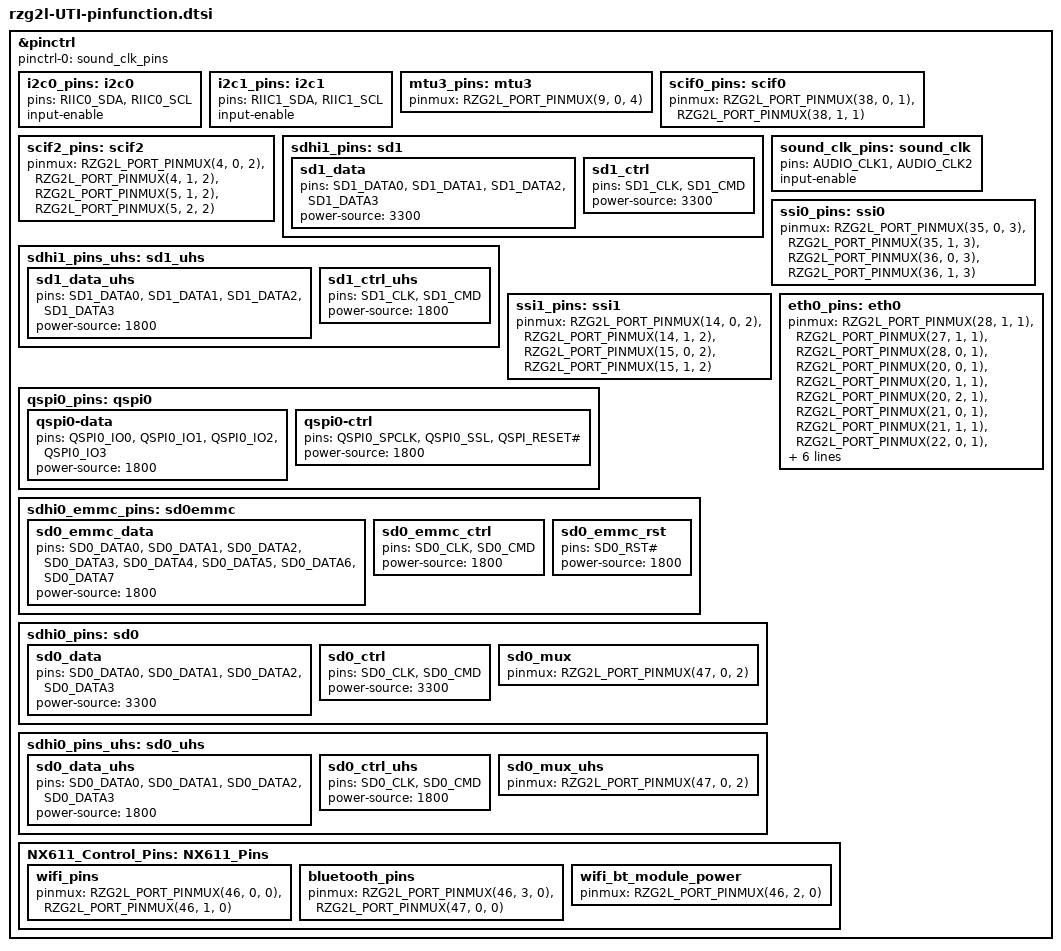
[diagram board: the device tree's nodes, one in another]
// SPDX-License-Identifier: (GPL-2.0-only OR BSD-2-Clause)
/*
 * Device Tree Source for the RZ/{G2L,V2L} SMARC pincontrol parts
 *
 * Copyright (C) 2021 Renesas Electronics Corp.
 */

#include <dt-bindings/gpio/gpio.h>
#include <dt-bindings/pinctrl/rzg2l-pinctrl.h>

&pinctrl {
	pinctrl-0 = <&sound_clk_pins>;
	pinctrl-names = "default";

	i2c0_pins: i2c0 {
		pins = "RIIC0_SDA", "RIIC0_SCL";
		input-enable;
	};

	i2c1_pins: i2c1 {
		pins = "RIIC1_SDA", "RIIC1_SCL";
		input-enable;
	};

	mtu3_pins: mtu3 {
		pinmux =
		        <RZG2L_PORT_PINMUX(9, 0, 4)>; // MTIOC2A 
	};

	scif0_pins: scif0 {
		pinmux = <RZG2L_PORT_PINMUX(38, 0, 1)>,	/* TxD */
			 <RZG2L_PORT_PINMUX(38, 1, 1)>;	/* RxD */
	};

        /* bluetooth */
	scif2_pins: scif2 {
		pinmux = <RZG2L_PORT_PINMUX(4, 0, 2)>, /* TxD */
			 <RZG2L_PORT_PINMUX(4, 1, 2)>, /* RxD */
			 <RZG2L_PORT_PINMUX(5, 1, 2)>, /* CTS# */
			 <RZG2L_PORT_PINMUX(5, 2, 2)>; /* RTS# */
	};

        /* wifi */
	sdhi1_pins: sd1 {
		sd1_data {
			pins = "SD1_DATA0", "SD1_DATA1", "SD1_DATA2", "SD1_DATA3";
			power-source = <3300>;
		};

		sd1_ctrl {
			pins = "SD1_CLK", "SD1_CMD";
			power-source = <3300>;
		};
	};

	sdhi1_pins_uhs: sd1_uhs {
		sd1_data_uhs {
			pins = "SD1_DATA0", "SD1_DATA1", "SD1_DATA2", "SD1_DATA3";
			power-source = <1800>;
		};

		sd1_ctrl_uhs {
			pins = "SD1_CLK", "SD1_CMD";
			power-source = <1800>;
		};
	};

	sound_clk_pins: sound_clk {
		pins = "AUDIO_CLK1", "AUDIO_CLK2";
		input-enable;
	};

        /* codec audio */
	ssi0_pins: ssi0 {
		pinmux = <RZG2L_PORT_PINMUX(35, 0, 3)>, /* BCK */
			 <RZG2L_PORT_PINMUX(35, 1, 3)>, /* RCK */
			 <RZG2L_PORT_PINMUX(36, 0, 3)>, /* TXD */
			 <RZG2L_PORT_PINMUX(36, 1, 3)>; /* RXD */
	};

	ssi1_pins: ssi1 {       /*Bluetooth Audio */
		pinmux = <RZG2L_PORT_PINMUX(14, 0, 2)>, /* BCK */
			 <RZG2L_PORT_PINMUX(14, 1, 2)>, /* RCK */
			 <RZG2L_PORT_PINMUX(15, 0, 2)>, /* TXD */
			 <RZG2L_PORT_PINMUX(15, 1, 2)>; /* RXD */
	};
	
	eth0_pins: eth0 {
		pinmux = <RZG2L_PORT_PINMUX(28, 1, 1)>, /* ET0_LINKSTA */
			 <RZG2L_PORT_PINMUX(27, 1, 1)>, /* ET0_MDC */
			 <RZG2L_PORT_PINMUX(28, 0, 1)>, /* ET0_MDIO */
			 <RZG2L_PORT_PINMUX(20, 0, 1)>, /* ET0_TXC */
			 <RZG2L_PORT_PINMUX(20, 1, 1)>, /* ET0_TX_CTL */
			 <RZG2L_PORT_PINMUX(20, 2, 1)>, /* ET0_TXD0 */
			 <RZG2L_PORT_PINMUX(21, 0, 1)>, /* ET0_TXD1 */
			 <RZG2L_PORT_PINMUX(21, 1, 1)>, /* ET0_TXD2 */
			 <RZG2L_PORT_PINMUX(22, 0, 1)>, /* ET0_TXD3 */
			 <RZG2L_PORT_PINMUX(24, 0, 1)>, /* ET0_RXC */
			 <RZG2L_PORT_PINMUX(24, 1, 1)>, /* ET0_RX_CTL */
			 <RZG2L_PORT_PINMUX(25, 0, 1)>, /* ET0_RXD0 */
			 <RZG2L_PORT_PINMUX(25, 1, 1)>, /* ET0_RXD1 */
			 <RZG2L_PORT_PINMUX(26, 0, 1)>, /* ET0_RXD2 */
			 <RZG2L_PORT_PINMUX(26, 1, 1)>; /* ET0_RXD3 */
	};

	/*gpio-sd0-pwr-en-hog {
		gpio-hog;
		gpios = <RZG2L_GPIO(4, 1) GPIO_ACTIVE_HIGH>;
		output-high;
		line-name = "gpio_sd0_pwr_en";
	};*/

	qspi0_pins: qspi0 {
		qspi0-data {
			pins = "QSPI0_IO0", "QSPI0_IO1", "QSPI0_IO2", "QSPI0_IO3";
			power-source = <1800>;
		};

		qspi0-ctrl {
			pins = "QSPI0_SPCLK", "QSPI0_SSL", "QSPI_RESET#";
			power-source = <1800>;
		};
	};

	sdhi0_emmc_pins: sd0emmc {
		sd0_emmc_data {
			pins = "SD0_DATA0", "SD0_DATA1", "SD0_DATA2", "SD0_DATA3",
			       "SD0_DATA4", "SD0_DATA5", "SD0_DATA6", "SD0_DATA7";
			power-source = <1800>;
		};

		sd0_emmc_ctrl {
			pins = "SD0_CLK", "SD0_CMD";
			power-source = <1800>;
		};

		sd0_emmc_rst {
			pins = "SD0_RST#";
			power-source = <1800>;
		};
	};

	sdhi0_pins: sd0 {
		sd0_data {
			pins = "SD0_DATA0", "SD0_DATA1", "SD0_DATA2", "SD0_DATA3";
			power-source = <3300>;
		};

		sd0_ctrl {
			pins = "SD0_CLK", "SD0_CMD";
			power-source = <3300>;
		};

		sd0_mux {
			pinmux = <RZG2L_PORT_PINMUX(47, 0, 2)>; /* SD0_CD */
		};
	};

	sdhi0_pins_uhs: sd0_uhs {
		sd0_data_uhs {
			pins = "SD0_DATA0", "SD0_DATA1", "SD0_DATA2", "SD0_DATA3";
			power-source = <1800>;
		};

		sd0_ctrl_uhs {
			pins = "SD0_CLK", "SD0_CMD";
			power-source = <1800>;
		};

		sd0_mux_uhs {
			pinmux = <RZG2L_PORT_PINMUX(47, 0, 2)>; /* SD0_CD */
		};
	};
	
	NX611_Control_Pins: NX611_Pins {
	        wifi_pins {
	                pinmux = <RZG2L_PORT_PINMUX(46, 0, 0)>, // wake 
	                         <RZG2L_PORT_PINMUX(46, 1, 0)>; // reset 
	        };
	        
	        bluetooth_pins {
	                pinmux = <RZG2L_PORT_PINMUX(46, 3, 0)>, // wake 
	                         <RZG2L_PORT_PINMUX(47, 0, 0)>; // reset 
	        };
	        
	        wifi_bt_module_power {
	                pinmux = <RZG2L_PORT_PINMUX(46, 2, 0)>;
	        };
	};
	
};

